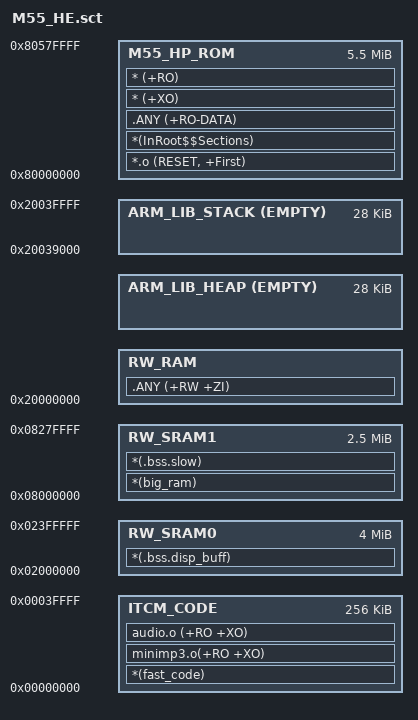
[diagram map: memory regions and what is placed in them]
#include "M55_HE_map.h"
#include "app_map.h"


/* MRAM code storage for M55-HE */
#define __ROM_BASE      0x80000000
#define __ROM_SIZE      0x00580000

#define __ITCM_BASE     0x00000000
#define __ITCM_SIZE     0x00040000

#define __DTCM_BASE     0x20000000
#define __DTCM_SIZE     0x00040000

#define __VECTORS_SIZE  (496 * 4)
#define __STACK_SIZE    0x00007000
#define __HEAP_SIZE     0x00007000

#define __SRAM0_BASE    0x02000000
#define __SRAM0_SIZE    0x00400000
#define __SRAM1_BASE    0x08000000
#define __SRAM1_SIZE    0x00280000

#define __STACK_TOP     (__DTCM_BASE + __DTCM_SIZE)
#define __HEAP_BASE     (AlignExpr(+0, 8))           /* starts after RW_RAM section, 8 byte aligned */
#define __APP_HEAP_BASE (AlignExpr(+0, 8))           /* starts after HEAP, 8 byte aligned */

LR_ROM __ROM_BASE NOCOMPRESS __ROM_SIZE  {    ; load region size_region
  M55_HP_ROM +0 __ROM_SIZE  {                 ; load address = execution address
   *.o (RESET, +First)
   *(InRoot$$Sections)
   .ANY (+RO-DATA)
    * (+XO)
    * (+RO)
  }

  ITCM_CODE __ITCM_BASE __ITCM_SIZE {
    /* lvgl fast code */
    *(fast_code)

    /* mp3 processing */
    minimp3.o(+RO +XO)
    audio.o (+RO +XO)
  }

  RW_RAM __DTCM_BASE {                     ; RW data
   .ANY (+RW +ZI)
  }

#if __HEAP_SIZE > 0
  ARM_LIB_HEAP  __HEAP_BASE EMPTY  __HEAP_SIZE  {   ; Reserve empty region for heap
  }
#endif

  ARM_LIB_STACK __STACK_TOP EMPTY -__STACK_SIZE {   ; Reserve empty region for stack
  }

  RW_SRAM0 __SRAM0_BASE __SRAM0_SIZE  {
   *(.bss.disp_buff)
  }

  RW_SRAM1 __SRAM1_BASE __SRAM1_SIZE {
    /* LVGL big RAM buffer */
    *(big_ram)

    /* fault handler data */
    *(.bss.slow)
  }
}
